VERSION ""

NS_ :

BS_:

BU_:

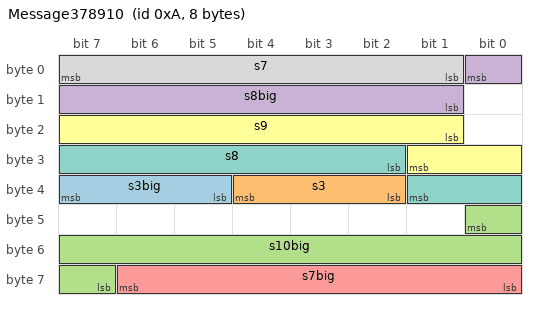
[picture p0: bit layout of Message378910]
BO_ 10 Message378910: 8 Vector__XXX
 SG_ s3big : 39|3@0- (1,0) [0|0] "" Vector__XXX
 SG_ s3 : 34|3@1- (1,0) [0|0] "" Vector__XXX
 SG_ s10big : 40|10@0- (1,0) [0|0] "" Vector__XXX
 SG_ s8big : 0|8@0- (1,0) [0|0] "" Vector__XXX
 SG_ s7big : 62|7@0- (1,0) [0|0] "" Vector__XXX
 SG_ s9 : 17|9@1- (1,0) [0|0] "" Vector__XXX
 SG_ s8 : 26|8@1- (1,0) [0|0] "" Vector__XXX
 SG_ s7 : 1|7@1- (1,0) [0|0] "" Vector__XXX

BO_ 9 Message63big_1: 8 Vector__XXX
 SG_ s63big : 6|63@0- (1,0) [0|0] "" Vector__XXX

BO_ 8 Message63_1: 8 Vector__XXX
 SG_ s63 : 1|63@1- (1,0) [0|0] "" Vector__XXX

BO_ 7 Message63big: 8 Vector__XXX
 SG_ s63big : 7|63@0- (1,0) [0|0] "" Vector__XXX

BO_ 6 Message63: 8 Vector__XXX
 SG_ s63 : 0|63@1- (1,0) [0|0] "" Vector__XXX

BO_ 5 Message32big: 8 Vector__XXX
 SG_ s32big : 7|32@0- (1,0) [0|0] "" Vector__XXX

BO_ 4 Message33big: 8 Vector__XXX
 SG_ s33big : 7|33@0- (1,0) [0|0] "" Vector__XXX

BO_ 3 Message64big: 8 Vector__XXX
 SG_ s64big : 7|64@0- (1,0) [0|0] "" Vector__XXX

BO_ 2 Message64: 8 Vector__XXX
 SG_ s64 : 0|64@1- (1,0) [-9.22337203685478E+018|9.22337203685478E+018] "" Vector__XXX

BO_ 1 Message33: 8 Vector__XXX
 SG_ s33 : 0|33@1- (1,0) [-4294967296|4294967295] "" Vector__XXX

BO_ 0 Message32: 8 Vector__XXX
 SG_ s32 : 0|32@1- (1,0) [0|0] "" Vector__XXX
